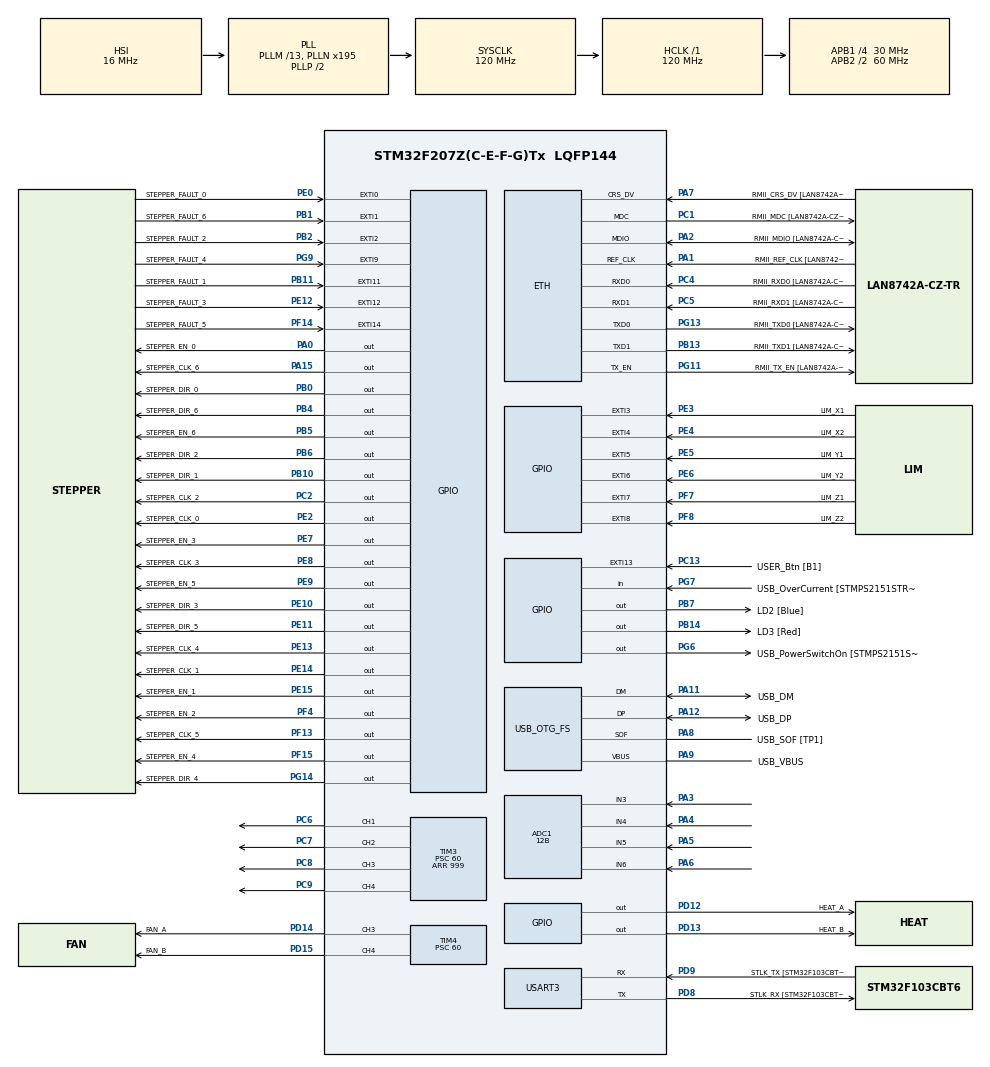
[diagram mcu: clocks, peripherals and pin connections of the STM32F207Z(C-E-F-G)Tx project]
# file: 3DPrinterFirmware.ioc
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ADC1.Channel-0\#ChannelRegularConversion=ADC_CHANNEL_3
ADC1.ClockPrescaler=ADC_CLOCK_SYNC_PCLK_DIV2
ADC1.ContinuousConvMode=DISABLE
ADC1.DMAContinuousRequests=ENABLE
ADC1.DataAlign=ADC_DATAALIGN_RIGHT
ADC1.DiscontinuousConvMode=DISABLE
ADC1.EOCSelection=ADC_EOC_SEQ_CONV
ADC1.EnableAnalogWatchDog=false
ADC1.ExternalTrigConv=ADC_SOFTWARE_START
ADC1.ExternalTrigConvEdge=ADC_EXTERNALTRIGCONVEDGE_NONE
ADC1.InjNumberOfConversion=0
ADC1.NbrOfConversion=1
ADC1.NbrOfConversionFlag=1
ADC1.Rank-0\#ChannelRegularConversion=1
ADC1.Resolution=ADC_RESOLUTION_12B
ADC1.SamplingTime-0\#ChannelRegularConversion=ADC_SAMPLETIME_112CYCLES
ADC1.ScanConvMode=ENABLE
ADC1.master=1
Dma.ADC1.0.Direction=DMA_PERIPH_TO_MEMORY
Dma.ADC1.0.FIFOMode=DMA_FIFOMODE_DISABLE
Dma.ADC1.0.Instance=DMA2_Stream0
Dma.ADC1.0.MemDataAlignment=DMA_MDATAALIGN_HALFWORD
Dma.ADC1.0.MemInc=DMA_MINC_ENABLE
Dma.ADC1.0.Mode=DMA_NORMAL
Dma.ADC1.0.PeriphDataAlignment=DMA_PDATAALIGN_HALFWORD
Dma.ADC1.0.PeriphInc=DMA_PINC_DISABLE
Dma.ADC1.0.Priority=DMA_PRIORITY_MEDIUM
Dma.Request0=ADC1
ETH.MediaInterface=ETH_MEDIA_INTERFACE_RMII
ETH.PHY_Name=LAN8742A_PHY_ADDRESS
ETH.PHY_Value=0
ETH.PhyAddress=0
FREERTOS.INCLUDE_xEventGroupSetBitFromISR=1
FREERTOS.INCLUDE_xTaskGetHandle=1
FREERTOS.INCLUDE_xTimerPendFunctionCall=1
FREERTOS.Tasks01=coordinatorTask,0,512,StartCoordinatorTask,Default,NULL,Dynamic,NULL,NULL
FREERTOS.configQUEUE_REGISTRY_SIZE=16
FREERTOS.configUSE_COUNTING_SEMAPHORES=1
FREERTOS.configUSE_RECURSIVE_MUTEXES=1
FREERTOS.configUSE_STATS_FORMATTING_FUNCTIONS=1
FREERTOS.configUSE_TIMERS=1
LWIP.LWIP_DNS=1
LWIP.MEMP_NUM_TCP_PCB=10
LWIP.MEMP_NUM_UDP_PCB=8
LWIP.Version=v2.0.0_Cube
Mcu.Family=STM32F2
Mcu.Name=STM32F207Z(C-E-F-G)Tx
Mcu.Package=LQFP144
NVIC.ADC_IRQn=true\:0\:0\:false\:false\:true\:false\:true
NVIC.DMA2_Stream0_IRQn=true\:5\:0\:false\:false\:true\:true\:true
NVIC.ETH_IRQn=true\:5\:0\:false\:false\:true\:true\:true
NVIC.EXTI0_IRQn=true\:5\:0\:false\:false\:true\:true\:true
NVIC.EXTI15_10_IRQn=true\:5\:0\:false\:false\:true\:true\:true
NVIC.EXTI1_IRQn=true\:5\:0\:false\:false\:true\:true\:true
NVIC.EXTI2_IRQn=true\:5\:0\:false\:false\:true\:true\:true
NVIC.EXTI3_IRQn=true\:5\:0\:false\:false\:true\:true\:true
NVIC.EXTI4_IRQn=true\:5\:0\:false\:false\:true\:true\:true
NVIC.EXTI9_5_IRQn=true\:5\:0\:false\:false\:true\:true\:true
NVIC.OTG_FS_IRQn=true\:5\:0\:false\:false\:true\:true\:true
NVIC.PriorityGroup=NVIC_PRIORITYGROUP_4
NVIC.TIM1_UP_TIM10_IRQn=true\:0\:0\:false\:false\:true\:false\:true
NVIC.TIM2_IRQn=true\:0\:0\:false\:false\:true\:false\:true
NVIC.TIM3_IRQn=true\:0\:0\:false\:false\:true\:false\:true
NVIC.TIM4_IRQn=true\:0\:0\:false\:false\:true\:false\:true
NVIC.TIM5_IRQn=true\:0\:0\:false\:false\:true\:false\:true
NVIC.TimeBase=TIM1_UP_TIM10_IRQn
NVIC.TimeBaseIP=TIM1
PA0-WKUP.GPIO_Label=STEPPER_EN_0
PA0-WKUP.Signal=GPIO_Output
PA1.GPIO_Label=RMII_REF_CLK [LAN8742A-CZ-TR_REFCLK0]
PA1.Mode=RMII
PA1.Signal=ETH_REF_CLK
PA10.GPIO_Label=USB_ID
PA10.Signal=USB_OTG_FS_ID
PA11.GPIO_Label=USB_DM
PA11.Mode=Device_Only
PA11.Signal=USB_OTG_FS_DM
PA12.GPIO_Label=USB_DP
PA12.Mode=Device_Only
PA12.Signal=USB_OTG_FS_DP
PA13.GPIO_Label=TMS
PA13.Mode=Serial_Wire
PA13.Signal=SYS_JTMS-SWDIO
PA14.GPIO_Label=TCK
PA14.Mode=Serial_Wire
PA14.Signal=SYS_JTCK-SWCLK
PA15.GPIO_Label=STEPPER_CLK_6
PA15.Signal=GPIO_Output
PA2.GPIO_Label=RMII_MDIO [LAN8742A-CZ-TR_MDIO]
PA2.Mode=RMII
PA2.Signal=ETH_MDIO
PA3.Signal=ADCx_IN3
PA4.Signal=ADCx_IN4
PA5.Signal=ADCx_IN5
PA6.Signal=ADCx_IN6
PA7.GPIO_Label=RMII_CRS_DV [LAN8742A-CZ-TR_CRS_DV]
PA7.Mode=RMII
PA7.Signal=ETH_CRS_DV
PA8.GPIO_Label=USB_SOF [TP1]
PA8.Mode=Activate_SOF_FS
PA8.Signal=USB_OTG_FS_SOF
PA9.GPIO_Label=USB_VBUS
PA9.Mode=Activate_VBUS
PA9.Signal=USB_OTG_FS_VBUS
PB0.GPIO_Label=STEPPER_DIR_0
PB0.Signal=GPIO_Output
PB1.GPIO_Label=STEPPER_FAULT_6
PB1.Signal=GPXTI1
PB10.GPIO_Label=STEPPER_DIR_1
PB10.Signal=GPIO_Output
PB11.GPIO_Label=STEPPER_FAULT_1
PB11.Signal=GPXTI11
PB13.GPIO_Label=RMII_TXD1 [LAN8742A-CZ-TR_TXD1]
PB13.Mode=RMII
PB13.Signal=ETH_TXD1
PB14.GPIO_Label=LD3 [Red]
PB14.Signal=GPIO_Output
PB2.GPIO_Label=STEPPER_FAULT_2
PB2.Signal=GPXTI2
PB3.GPIO_Label=SWO
PB3.Signal=SYS_JTDO-SWO
PB4.GPIO_Label=STEPPER_DIR_6
PB4.Signal=GPIO_Output
PB5.GPIO_Label=STEPPER_EN_6
PB5.Signal=GPIO_Output
PB6.GPIO_Label=STEPPER_DIR_2
PB6.Signal=GPIO_Output
PB7.GPIO_Label=LD2 [Blue]
PB7.Signal=GPIO_Output
PC1.GPIO_Label=RMII_MDC [LAN8742A-CZ-TR_MDC]
PC1.Mode=RMII
PC1.Signal=ETH_MDC
PC13.GPIO_Label=USER_Btn [B1]
PC13.Signal=GPXTI13
PC14-OSC32_IN.Mode=LSE-External-Oscillator
PC14-OSC32_IN.Signal=RCC_OSC32_IN
PC15-OSC32_OUT.Mode=LSE-External-Oscillator
PC15-OSC32_OUT.Signal=RCC_OSC32_OUT
PC2.GPIO_Label=STEPPER_CLK_2
PC2.Signal=GPIO_Output
PC4.GPIO_Label=RMII_RXD0 [LAN8742A-CZ-TR_RXD0]
PC4.Mode=RMII
PC4.Signal=ETH_RXD0
PC5.GPIO_Label=RMII_RXD1 [LAN8742A-CZ-TR_RXD1]
PC5.Mode=RMII
PC5.Signal=ETH_RXD1
PC6.Signal=S_TIM3_CH1
PC7.Signal=S_TIM3_CH2
PC8.Signal=S_TIM3_CH3
PC9.Signal=S_TIM3_CH4
PD12.GPIO_Label=HEAT_A
PD12.Signal=GPIO_Output
PD13.GPIO_Label=HEAT_B
PD13.Signal=GPIO_Output
PD14.GPIO_Label=FAN_A
PD14.Signal=S_TIM4_CH3
PD15.GPIO_Label=FAN_B
PD15.Signal=S_TIM4_CH4
PD8.GPIO_Label=STLK_RX [STM32F103CBT6_PA3]
PD8.Mode=Asynchronous
PD8.Signal=USART3_TX
PD9.GPIO_Label=STLK_TX [STM32F103CBT6_PA2]
PD9.Mode=Asynchronous
PD9.Signal=USART3_RX
PE0.GPIO_Label=STEPPER_FAULT_0
PE0.Signal=GPXTI0
PE10.GPIO_Label=STEPPER_DIR_3
PE10.Signal=GPIO_Output
PE11.GPIO_Label=STEPPER_DIR_5
PE11.Signal=GPIO_Output
PE12.GPIO_Label=STEPPER_FAULT_3
PE12.Signal=GPXTI12
PE13.GPIO_Label=STEPPER_CLK_4
PE13.Signal=GPIO_Output
PE14.GPIO_Label=STEPPER_CLK_1
PE14.Signal=GPIO_Output
PE15.GPIO_Label=STEPPER_EN_1
PE15.Signal=GPIO_Output
PE2.GPIO_Label=STEPPER_CLK_0
PE2.Signal=GPIO_Output
PE3.GPIO_Label=LIM_X1
PE3.Signal=GPXTI3
PE4.GPIO_Label=LIM_X2
PE4.Signal=GPXTI4
PE5.GPIO_Label=LIM_Y1
PE5.Signal=GPXTI5
PE6.GPIO_Label=LIM_Y2
PE6.Signal=GPXTI6
PE7.GPIO_Label=STEPPER_EN_3
PE7.Signal=GPIO_Output
PE8.GPIO_Label=STEPPER_CLK_3
PE8.Signal=GPIO_Output
PE9.GPIO_Label=STEPPER_EN_5
PE9.Signal=GPIO_Output
PF13.GPIO_Label=STEPPER_CLK_5
PF13.Signal=GPIO_Output
PF14.GPIO_Label=STEPPER_FAULT_5
PF14.Signal=GPXTI14
PF15.GPIO_Label=STEPPER_EN_4
PF15.Signal=GPIO_Output
PF4.GPIO_Label=STEPPER_EN_2
PF4.Signal=GPIO_Output
PF7.GPIO_Label=LIM_Z1
PF7.Signal=GPXTI7
PF8.GPIO_Label=LIM_Z2
PF8.Signal=GPXTI8
PG11.GPIO_Label=RMII_TX_EN [LAN8742A-CZ-TR_TXEN]
PG11.Mode=RMII
PG11.Signal=ETH_TX_EN
PG13.GPIO_Label=RMII_TXD0 [LAN8742A-CZ-TR_TXD0]
PG13.Mode=RMII
PG13.Signal=ETH_TXD0
PG14.GPIO_Label=STEPPER_DIR_4
PG14.Signal=GPIO_Output
PG6.GPIO_Label=USB_PowerSwitchOn [STMPS2151STR_EN]
PG6.Signal=GPIO_Output
PG7.GPIO_Label=USB_OverCurrent [STMPS2151STR_FAULT]
PG7.Signal=GPIO_Input
PG9.GPIO_Label=STEPPER_FAULT_4
PG9.Signal=GPXTI9
PH0-OSC_IN.GPIO_Label=MCO [STM32F103CBT6_PA8]
PH0-OSC_IN.Mode=HSE-External-Clock-Source
PH0-OSC_IN.Signal=RCC_OSC_IN
PH1-OSC_OUT.Mode=HSE-External-Clock-Source
PH1-OSC_OUT.Signal=RCC_OSC_OUT
ProjectManager.HeapSize=0x200
ProjectManager.StackSize=0x400
ProjectManager.TargetToolchain=SW4STM32
RCC.48MHZClocksFreq_Value=48000000
RCC.AHBFreq_Value=120000000
RCC.APB1CLKDivider=RCC_HCLK_DIV4
RCC.APB1Freq_Value=30000000
RCC.APB1TimFreq_Value=60000000
RCC.APB2CLKDivider=RCC_HCLK_DIV2
RCC.APB2Freq_Value=60000000
RCC.APB2TimFreq_Value=120000000
RCC.CortexFreq_Value=120000000
RCC.HCLKFreq_Value=120000000
RCC.HSE_VALUE=8000000
RCC.HSI_VALUE=16000000
RCC.PLLM=13
RCC.PLLMUL=RCC_PLL_MUL9
RCC.PLLN=195
RCC.PLLQ=5
RCC.PRESCALERUSB=RCC_USBCLKSOURCE_PLL_DIV1_5
RCC.SYSCLKFreq_VALUE=120000000
RCC.SYSCLKSource=RCC_SYSCLKSOURCE_PLLCLK
RCC.SYSCLKSourceVirtual=RCC_SYSCLKSOURCE_PLLCLK
RCC.USBFreq_Value=48000000
RCC.VCOOutputFreq_Value=240000000
SH.ADCx_IN3.0=ADC1_IN3,IN3
SH.ADCx_IN4.0=ADC1_IN4,IN4
SH.ADCx_IN5.0=ADC1_IN5,IN5
SH.ADCx_IN6.0=ADC1_IN6,IN6
SH.S_TIM3_CH1.0=TIM3_CH1,PWM Generation1 CH1
SH.S_TIM3_CH2.0=TIM3_CH2,PWM Generation2 CH2
SH.S_TIM3_CH3.0=TIM3_CH3,PWM Generation3 CH3
SH.S_TIM3_CH4.0=TIM3_CH4,PWM Generation4 CH4
SH.S_TIM4_CH3.0=TIM4_CH3,PWM Generation3 CH3
SH.S_TIM4_CH4.0=TIM4_CH4,PWM Generation4 CH4
TIM2.Period=99
TIM2.Prescaler=30
TIM3.Channel-PWM\ Generation1\ CH1=TIM_CHANNEL_1
TIM3.Channel-PWM\ Generation2\ CH2=TIM_CHANNEL_2
TIM3.Channel-PWM\ Generation3\ CH3=TIM_CHANNEL_3
TIM3.Channel-PWM\ Generation4\ CH4=TIM_CHANNEL_4
TIM3.Period=999
TIM3.Prescaler=60
TIM4.Channel-PWM\ Generation3\ CH3=TIM_CHANNEL_3
TIM4.Channel-PWM\ Generation4\ CH4=TIM_CHANNEL_4
TIM4.Period=999
TIM4.Prescaler=60
TIM5.Period=9999
TIM5.Prescaler=6000
TIM5.TIM_MasterOutputTrigger=TIM_TRGO_UPDATE
TIM5.TIM_MasterSlaveMode=TIM_MASTERSLAVEMODE_DISABLE
USART3.VirtualMode=VM_ASYNC
USB_DEVICE.CLASS_NAME_FS=CDC
USB_DEVICE.VirtualMode-CDC_FS=Cdc
USB_DEVICE.VirtualModeFS=Cdc_FS
USB_OTG_FS.VirtualMode=Device_Only
VP_FREERTOS_VS_ENABLE.Mode=Enabled
VP_LWIP_VS_Enabled.Mode=Enabled
VP_SYS_VS_tim1.Mode=TIM1
VP_TIM2_VS_ClockSourceINT.Mode=Internal
VP_TIM3_VS_ClockSourceINT.Mode=Internal
VP_TIM4_VS_ClockSourceINT.Mode=Internal
VP_TIM5_VS_ClockSourceINT.Mode=Internal
VP_USB_DEVICE_VS_USB_DEVICE_CDC_FS.Mode=CDC_FS
board=NUCLEO-F207ZG

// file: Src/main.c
/**
  ******************************************************************************
  * File Name          : main.c
  * Description        : Main program body
  ******************************************************************************
  * This notice applies to any and all portions of this file
  * that are not between comment pairs USER CODE BEGIN and
  * USER CODE END. Other portions of this file, whether
  * inserted by the user or by software development tools
  * are owned by their respective copyright owners.
  *
  * Copyright (c) 2017 STMicroelectronics International N.V.
  * All rights reserved.
  *
  * Redistribution and use in source and binary forms, with or without
  * modification, are permitted, provided that the following conditions are met:
  *
  * 1. Redistribution of source code must retain the above copyright notice,
  *    this list of conditions and the following disclaimer.
  * 2. Redistributions in binary form must reproduce the above copyright notice,
  *    this list of conditions and the following disclaimer in the documentation
  *    and/or other materials provided with the distribution.
  * 3. Neither the name of STMicroelectronics nor the names of other
  *    contributors to this software may be used to endorse or promote products
  *    derived from this software without specific written permission.
  * 4. This software, including modifications and/or derivative works of this
  *    software, must execute solely and exclusively on microcontroller or
  *    microprocessor devices manufactured by or for STMicroelectronics.
  * 5. Redistribution and use of this software other than as permitted under
  *    this license is void and will automatically terminate your rights under
  *    this license.
  *
  * THIS SOFTWARE IS PROVIDED BY STMICROELECTRONICS AND CONTRIBUTORS "AS IS"
  * AND ANY EXPRESS, IMPLIED OR STATUTORY WARRANTIES, INCLUDING, BUT NOT
  * LIMITED TO, THE IMPLIED WARRANTIES OF MERCHANTABILITY, FITNESS FOR A
  * PARTICULAR PURPOSE AND NON-INFRINGEMENT OF THIRD PARTY INTELLECTUAL PROPERTY
  * RIGHTS ARE DISCLAIMED TO THE FULLEST EXTENT PERMITTED BY LAW. IN NO EVENT
  * SHALL STMICROELECTRONICS OR CONTRIBUTORS BE LIABLE FOR ANY DIRECT, INDIRECT,
  * INCIDENTAL, SPECIAL, EXEMPLARY, OR CONSEQUENTIAL DAMAGES (INCLUDING, BUT NOT
  * LIMITED TO, PROCUREMENT OF SUBSTITUTE GOODS OR SERVICES; LOSS OF USE, DATA,
  * OR PROFITS; OR BUSINESS INTERRUPTION) HOWEVER CAUSED AND ON ANY THEORY OF
  * LIABILITY, WHETHER IN CONTRACT, STRICT LIABILITY, OR TORT (INCLUDING
  * NEGLIGENCE OR OTHERWISE) ARISING IN ANY WAY OUT OF THE USE OF THIS SOFTWARE,
  * EVEN IF ADVISED OF THE POSSIBILITY OF SUCH DAMAGE.
  *
  ******************************************************************************
  */
#include "main.h"
#include "stm32f2xx_hal.h"
#include "cmsis_os.h"
#include "adc.h"
#include "dma.h"
#include "lwip.h"
#include "tim.h"
#include "usart.h"
#include "usb_device.h"
#include "gpio.h"

/* USER CODE BEGIN Includes */

#include "stepper.h"
#include "heater.h"

/* USER CODE END Includes */

/* USER CODE BEGIN PV */
/* Private variables ---------------------------------------------------------*/

/* USER CODE END PV */

void SystemClock_Config(void);
void MX_FREERTOS_Init(void);

/* USER CODE BEGIN PFP */
/* Private function prototypes -----------------------------------------------*/

/* USER CODE END PFP */

int main(void)
{

  /* MCU Configuration----------------------------------------------------------*/

  /* Reset of all peripherals, Initializes the Flash interface and the Systick. */
  HAL_Init();

  /* Configure the system clock */
  SystemClock_Config();

  /* Initialize all configured peripherals */
  MX_GPIO_Init();
  MX_DMA_Init();
  MX_USART3_UART_Init();
  MX_ADC1_Init();
  MX_TIM4_Init();
  MX_TIM3_Init();
  MX_TIM2_Init();
  MX_TIM5_Init();

  /* Call init function for freertos objects (in freertos.c) */
  MX_FREERTOS_Init();

  /* Start scheduler */
  osKernelStart();

  /* We should never get here as control is now taken by the scheduler */

  /* Infinite loop */
  while (1)
  {

  }

}

/** System Clock Configuration
*/
void SystemClock_Config(void)
{

  RCC_OscInitTypeDef RCC_OscInitStruct;
  RCC_ClkInitTypeDef RCC_ClkInitStruct;

    /**Initializes the CPU, AHB and APB busses clocks
    */
  RCC_OscInitStruct.OscillatorType = RCC_OSCILLATORTYPE_HSI;
  RCC_OscInitStruct.HSIState = RCC_HSI_ON;
  RCC_OscInitStruct.HSICalibrationValue = 16;
  RCC_OscInitStruct.PLL.PLLState = RCC_PLL_ON;
  RCC_OscInitStruct.PLL.PLLSource = RCC_PLLSOURCE_HSI;
  RCC_OscInitStruct.PLL.PLLM = 13;
  RCC_OscInitStruct.PLL.PLLN = 195;
  RCC_OscInitStruct.PLL.PLLP = RCC_PLLP_DIV2;
  RCC_OscInitStruct.PLL.PLLQ = 5;
  if (HAL_RCC_OscConfig(&RCC_OscInitStruct) != HAL_OK)
  {
    _Error_Handler(__FILE__, __LINE__);
  }

    /**Initializes the CPU, AHB and APB busses clocks
    */
  RCC_ClkInitStruct.ClockType = RCC_CLOCKTYPE_HCLK|RCC_CLOCKTYPE_SYSCLK
                              |RCC_CLOCKTYPE_PCLK1|RCC_CLOCKTYPE_PCLK2;
  RCC_ClkInitStruct.SYSCLKSource = RCC_SYSCLKSOURCE_PLLCLK;
  RCC_ClkInitStruct.AHBCLKDivider = RCC_SYSCLK_DIV1;
  RCC_ClkInitStruct.APB1CLKDivider = RCC_HCLK_DIV4;
  RCC_ClkInitStruct.APB2CLKDivider = RCC_HCLK_DIV2;

  if (HAL_RCC_ClockConfig(&RCC_ClkInitStruct, FLASH_LATENCY_3) != HAL_OK)
  {
    _Error_Handler(__FILE__, __LINE__);
  }

    /**Configure the Systick interrupt time
    */
  HAL_SYSTICK_Config(HAL_RCC_GetHCLKFreq()/1000);

    /**Configure the Systick
    */
  HAL_SYSTICK_CLKSourceConfig(SYSTICK_CLKSOURCE_HCLK);

  /* SysTick_IRQn interrupt configuration */
  HAL_NVIC_SetPriority(SysTick_IRQn, 15, 0);
}

void HAL_TIM_PeriodElapsedCallback(TIM_HandleTypeDef *htim)
{
  if (htim->Instance == TIM1) {
    HAL_IncTick();
  }
/* USER CODE BEGIN Callback 1 */

  if (htim->Instance == TIM5) {
	  heater_start_conversion();
  }
//
//  if (htim->Instance == TIM2) {
//	  stepper_timer_callback();
//  }

/* USER CODE END Callback 1 */
}

void _Error_Handler(char * file, int line)
{
  while(1)
  {
  }
}

/************************ (C) COPYRIGHT STMicroelectronics *****END OF FILE****/

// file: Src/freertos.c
/**
  ******************************************************************************
  * File Name          : freertos.c
  * Description        : Code for freertos applications
  ******************************************************************************
  * This notice applies to any and all portions of this file
  * that are not between comment pairs USER CODE BEGIN and
  * USER CODE END. Other portions of this file, whether
  * inserted by the user or by software development tools
  * are owned by their respective copyright owners.
  *
  * Copyright (c) 2017 STMicroelectronics International N.V.
  * All rights reserved.
  *
  * Redistribution and use in source and binary forms, with or without
  * modification, are permitted, provided that the following conditions are met:
  *
  * 1. Redistribution of source code must retain the above copyright notice,
  *    this list of conditions and the following disclaimer.
  * 2. Redistributions in binary form must reproduce the above copyright notice,
  *    this list of conditions and the following disclaimer in the documentation
  *    and/or other materials provided with the distribution.
  * 3. Neither the name of STMicroelectronics nor the names of other
  *    contributors to this software may be used to endorse or promote products
  *    derived from this software without specific written permission.
  * 4. This software, including modifications and/or derivative works of this
  *    software, must execute solely and exclusively on microcontroller or
  *    microprocessor devices manufactured by or for STMicroelectronics.
  * 5. Redistribution and use of this software other than as permitted under
  *    this license is void and will automatically terminate your rights under
  *    this license.
  *
  * THIS SOFTWARE IS PROVIDED BY STMICROELECTRONICS AND CONTRIBUTORS "AS IS"
  * AND ANY EXPRESS, IMPLIED OR STATUTORY WARRANTIES, INCLUDING, BUT NOT
  * LIMITED TO, THE IMPLIED WARRANTIES OF MERCHANTABILITY, FITNESS FOR A
  * PARTICULAR PURPOSE AND NON-INFRINGEMENT OF THIRD PARTY INTELLECTUAL PROPERTY
  * RIGHTS ARE DISCLAIMED TO THE FULLEST EXTENT PERMITTED BY LAW. IN NO EVENT
  * SHALL STMICROELECTRONICS OR CONTRIBUTORS BE LIABLE FOR ANY DIRECT, INDIRECT,
  * INCIDENTAL, SPECIAL, EXEMPLARY, OR CONSEQUENTIAL DAMAGES (INCLUDING, BUT NOT
  * LIMITED TO, PROCUREMENT OF SUBSTITUTE GOODS OR SERVICES; LOSS OF USE, DATA,
  * OR PROFITS; OR BUSINESS INTERRUPTION) HOWEVER CAUSED AND ON ANY THEORY OF
  * LIABILITY, WHETHER IN CONTRACT, STRICT LIABILITY, OR TORT (INCLUDING
  * NEGLIGENCE OR OTHERWISE) ARISING IN ANY WAY OUT OF THE USE OF THIS SOFTWARE,
  * EVEN IF ADVISED OF THE POSSIBILITY OF SUCH DAMAGE.
  *
  ******************************************************************************
  */

#include "FreeRTOS.h"
#include "task.h"
#include "cmsis_os.h"

/* USER CODE BEGIN Includes */
#include "gpio.h"
#include "heater.h"
/* USER CODE END Includes */

osThreadId coordinatorTaskHandle;

void StartCoordinatorTask(void const * argument);

extern void MX_USB_DEVICE_Init(void);
extern void MX_LWIP_Init(void);
void MX_FREERTOS_Init(void); /* (MISRA C 2004 rule 8.1) */

/* Hook prototypes */

/* Init FreeRTOS */

void MX_FREERTOS_Init(void) {

  /* Create the thread(s) */
  /* definition and creation of coordinatorTask */
  osThreadDef(coordinatorTask, StartCoordinatorTask, osPriorityNormal, 0, 512);
  coordinatorTaskHandle = osThreadCreate(osThread(coordinatorTask), NULL);

}

/* StartCoordinatorTask function */
void StartCoordinatorTask(void const * argument)
{
  /* init code for USB_DEVICE */
  MX_USB_DEVICE_Init();

  /* init code for LWIP */
  MX_LWIP_Init();

  /* USER CODE BEGIN StartCoordinatorTask */

  heater_init();
  heater_channel_set_coefficients(0, 0.0008153169516, 0.0001942452380, 0.0000002152347432);
  heater_channel_set_port(0, HEAT_A_GPIO_Port, HEAT_A_Pin);
  heater_channel_set_temp(0, 200.0);
  heater_channel_set_enabled(0, true);
  heater_start();

  /* Infinite loop */
  for(;;)
  {
    osDelay(1);
  }
  /* USER CODE END StartCoordinatorTask */
}

/************************ (C) COPYRIGHT STMicroelectronics *****END OF FILE****/
